AUTOSAR XML (schema 4-2-2)
package /Components
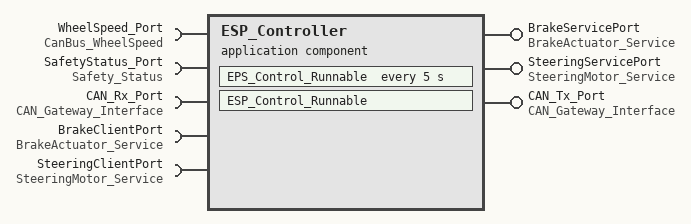
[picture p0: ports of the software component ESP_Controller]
  application sw component type ESP_Controller
    provide port BrakeServicePort: provided-interface=BrakeActuator_Service
    provide port SteeringServicePort: provided-interface=SteeringMotor_Service
    provide port CAN_Tx_Port: provided-interface=CAN_Gateway_Interface
    5 x require port:
      WheelSpeed_Port: required-interface=CanBus_WheelSpeed
      SafetyStatus_Port: required-interface=Safety_Status
      CAN_Rx_Port: required-interface=CAN_Gateway_Interface
      BrakeClientPort: required-interface=BrakeActuator_Service
      SteeringClientPort: required-interface=SteeringMotor_Service
    behavior ESP_Controller_Behavior
      external trigger occurred event Slip_Detected_Trigger: start-on-event=Process_WheelSpeeds
      timing event ESP_Main_5ms: start-on-event=EPS_Control_Runnable, period=5
      runnable ESP_Control_Runnable: minimum-start-interval=5, symbol=ESP_Control_Runnable_Symbol
        data-receive-point-by-values:
          5 x access:
            WheelSpeed_Access: accessed-variable=WheelSpeed_Port.WheelSpeed
            YawRate_Access: accessed-variable=CAN_Rx_Port.YawRate
            LateralAccel_Access: accessed-variable=CAN_Rx_Port.LateralAcceleration
            SteeringAngle_Access: accessed-variable=CAN_Rx_Port.SteeringAngle
            SafetyStatus_Access: accessed-variable=SafetyStatus_Port.SafetyStatus
        sync call Call_BrakeActuator: called-from-within-exclusive-area=ESP_EA, operation=BrakeClientPort.SetBrake, timeout=5
        sync call Call_SteeringMotor: called-from-within-exclusive-area=ESP_EA, operation=SteeringClientPort.SetSteering, timeout=10
